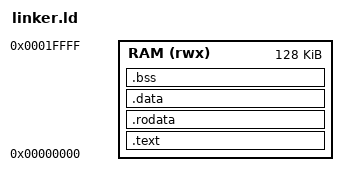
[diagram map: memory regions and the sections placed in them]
MEMORY
{
    RAM (rwx) : ORIGIN = 0x00000000, LENGTH = 128K
}

SECTIONS
{
    .text : {
        *(.text.init)
        *(.text*)
    } > RAM

    .rodata : {
        . = ALIGN(4);
        *(.rodata*)
        *(.srodata*)
    } > RAM

    .data : {
        . = ALIGN(4);
        *(.data*)
        *(.sdata*)
        __global_pointer$ = . + 0x800;
    } > RAM

    .bss : {
        . = ALIGN(4);
        _sbss = .;
        *(.bss*)
        *(.sbss*)
        *(COMMON)
        _ebss = .;
    } > RAM

    . = ALIGN(4);
    _stack_top = ORIGIN(RAM) + LENGTH(RAM);
}

